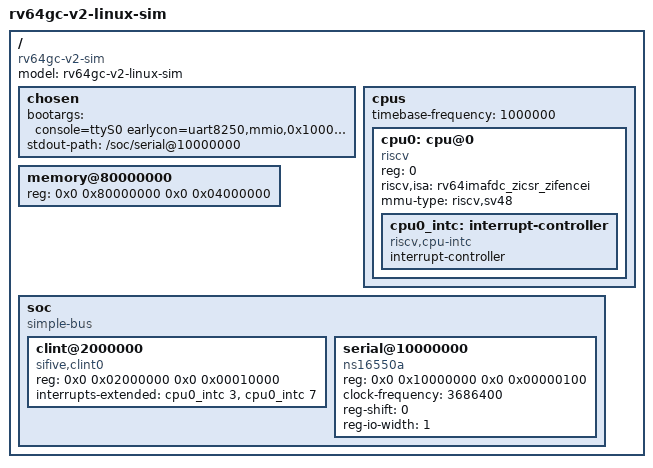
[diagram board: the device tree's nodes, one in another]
/dts-v1/;

/ {
    #address-cells = <2>;
    #size-cells = <2>;
    compatible = "rv64gc-v2-sim";
    model = "rv64gc-v2-linux-sim";

    chosen {
        bootargs = "console=ttyS0 earlycon=uart8250,mmio,0x10000000 loglevel=8 ignore_loglevel nokaslr no5lvl";
        stdout-path = "/soc/serial@10000000";
    };

    cpus {
        #address-cells = <1>;
        #size-cells = <0>;
        timebase-frequency = <1000000>;

        cpu0: cpu@0 {
            device_type = "cpu";
            reg = <0>;
            compatible = "riscv";
            riscv,isa = "rv64imafdc_zicsr_zifencei";
            mmu-type = "riscv,sv48";
            status = "okay";

            cpu0_intc: interrupt-controller {
                #address-cells = <0>;
                #interrupt-cells = <1>;
                compatible = "riscv,cpu-intc";
                interrupt-controller;
            };
        };
    };

    memory@80000000 {
        device_type = "memory";
        reg = <0x0 0x80000000 0x0 0x04000000>;
    };

    soc {
        #address-cells = <2>;
        #size-cells = <2>;
        compatible = "simple-bus";
        ranges;

        clint@2000000 {
            compatible = "sifive,clint0", "riscv,clint0";
            reg = <0x0 0x02000000 0x0 0x00010000>;
            interrupts-extended = <&cpu0_intc 3>, <&cpu0_intc 7>;
        };

        serial@10000000 {
            compatible = "ns16550a";
            reg = <0x0 0x10000000 0x0 0x00000100>;
            clock-frequency = <3686400>;
            reg-shift = <0>;
            reg-io-width = <1>;
        };
    };
};
